# ISS_CCP2 register map
Vendor: Texas Instruments
Peripheral module from a debugger description file (folder omap5430_ES2_PUBLIC).
Registers are 32-bit, access per field, reset values left out (the file's numbers can be read two ways) unless marked. A register's access mark holds for its fields unless they carry their own. Offsets are as the file gives them; lines under a group give offsets from that group; [hi:lo] are bit positions; {n}, {i} and the like mark numbered series; 'fields as' and 'values as' point back to an identical list; <NAME> marks a mode.

## ISS_CCP2
0x00 CCP2_REVISION ro — IP Revision Identifier (X.Y.R) Used by software to track features, bugs, and compatibility
  [31:0] REVISION — IP revision
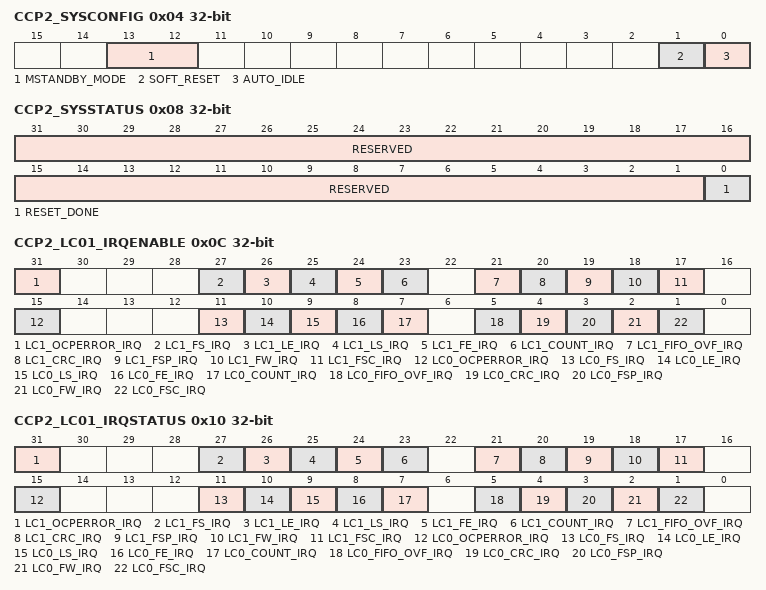
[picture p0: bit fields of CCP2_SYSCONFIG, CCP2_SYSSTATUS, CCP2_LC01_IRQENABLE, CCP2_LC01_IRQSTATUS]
0x04 CCP2_SYSCONFIG — SYSTEM CONFIGURATION REGISTER This register is the OCP-socket system configuration register.
  [13:12] MSTANDBY_MODE rw — Sets the behavior of the master port power management signals.
    0=ForceStby (Force-standby. MStandby is only asserted when the module is disabled.); 1=NoStdby (No-standby. MStandby is never asserted.); 2=SmartStdby (Smart-standby: MStandby is asserted based on the activity of the module. The module will try to go to standby during the vertical blanking period.)
  [1] SOFT_RESET rw — Software reset. Set the bit to 1 to trigger a module reset. The bit is automatically reset by the hardware. During reads return 0.
    0=Normal mode; 1=Reset (The module is reset)
  [0] AUTO_IDLE rw — Internal OCP clock gating strategy.
    0=Free (OCP clock is free-running.); 1=Gated (Automatic OCP clock gating strategy is applied based on the OCP interface activity.)
0x08 CCP2_SYSSTATUS ro — SYSTEM STATUS REGISTER This register provides status information about the module, excluding the interrupt status register.
  [31:1] RESERVED — Write 0's for future compatibility. Reads returns 0.
  [0] RESET_DONE — Internal reset monitoring
    1=ResetCompleted; 0=ResetOngoing (Internal module reset is on going.)
0x0C CCP2_LC01_IRQENABLE — INTERRUPT ENABLE REGISTER - LOG CHAN 0 & 1 This register regroups all the events related to logical channel 0 and logical channel 1. The events related to logical channel 0 trigger SINTERRUPTN[0]. The events related to logical channel 1 trigger SINTERRUPTN[1]. The channel must be enabled for events to be generated on that channel.
  [all] fields
    0=Disable (Event is masked); 1=Enable (Event generates an interrupt when it occurs)
  [31] LC1_OCPERROR_IRQ rw — An OCP error occurred on the master write port.
  [27] LC1_FS_IRQ rw — Logical channel 1 - Frame start sync code detection.
  [26] LC1_LE_IRQ rw — Logical channel 1 - Line end sync code detection.
  [25] LC1_LS_IRQ rw — Logical channel 1 - Line start sync code detection.
  [24] LC1_FE_IRQ rw — Logical channel 1 - Frame end sync code detection.
  [23] LC1_COUNT_IRQ rw — Logical channel 1 - Frame counter reached.
  [21] LC1_FIFO_OVF_IRQ rw — Logical channel 1 - FIFO overflow error.
  [20] LC1_CRC_IRQ rw — Logical channel 1 - CRC error.
  [19] LC1_FSP_IRQ rw — Logical channel 1 - FSP error.
  [18] LC1_FW_IRQ rw — Logical channel 1 - Frame width error.
  [17] LC1_FSC_IRQ rw — Logical channel 1 - False sync code error.
  [15] LC0_OCPERROR_IRQ rw — An OCP error occurred on the master write port.
  [11] LC0_FS_IRQ rw — Logical channel 0 - Frame start sync code detection.
  [10] LC0_LE_IRQ rw — Logical channel 0 - Line end sync code detection.
  [9] LC0_LS_IRQ rw — Logical channel 0 - Line start sync code detection.
  [8] LC0_FE_IRQ rw — Logical channel 0 - Frame end sync code detection.
  [7] LC0_COUNT_IRQ rw — Logical channel 0 - Frame counter reached.
  [5] LC0_FIFO_OVF_IRQ rw — Logical channel 0 - FIFO overflow error.
  [4] LC0_CRC_IRQ rw — Logical channel 0 - CRC error.
  [3] LC0_FSP_IRQ rw — Logical channel 0 - FSP error.
  [2] LC0_FW_IRQ rw — Logical channel 0 - Frame width error.
  [1] LC0_FSC_IRQ rw — Logical channel 0 - False sync code error.
0x10 CCP2_LC01_IRQSTATUS access not given — INTERRUPT STATUS REGISTER - LOG CHAN 0 & 1 This register regroups all the events related to logical channel 0 and logical channel 1. The events related to logical channel 0 trigger SINTERRUPTN[0]. The events related to logical channel 1 trigger SINTERRUPTN[1]. The channel must be enabled for events to be generated on that channel.
  [all] fields
    0=False (READS: Event is false. WRITES: Status bit unchanged.); 1=True (READS: Event is true (pending). WRITES: Status bit is reset.)
  [31] LC1_OCPERROR_IRQ — An OCP error occurred on the master write port. (access RW W1toClr)
  [27] LC1_FS_IRQ — Logical channel 1 - Frame start sync code detection status. (access RW W1toClr)
  [26] LC1_LE_IRQ — Logical channel 1 - Line end sync code detection status. (access RW W1toClr)
  [25] LC1_LS_IRQ — Logical channel 1 - Line start sync code detection status. (access RW W1toClr)
  [24] LC1_FE_IRQ — Logical channel 1 - Frame end sync code detection status. (access RW W1toClr)
  [23] LC1_COUNT_IRQ — Logical channel 1 - Frame counter reached status. (access RW W1toClr)
  [21] LC1_FIFO_OVF_IRQ — Logical channel 1 - FIFO overflow error status. (access RW W1toClr)
  [20] LC1_CRC_IRQ — Logical channel 1 - CRC error status. (access RW W1toClr)
  [19] LC1_FSP_IRQ — Logical channel 1 - FSP error status. (access RW W1toClr)
  [18] LC1_FW_IRQ — Logical channel 1 - Frame width error status. (access RW W1toClr)
  [17] LC1_FSC_IRQ — Logical channel 1 - False sync code error status. (access RW W1toClr)
  [15] LC0_OCPERROR_IRQ — An OCP error occurred on the master write port. (access RW W1toClr)
  [11] LC0_FS_IRQ — Logical channel 0 - Frame start sync code detection status. (access RW W1toClr)
  [10] LC0_LE_IRQ — Logical channel 0 - Line end sync code detection status. (access RW W1toClr)
  [9] LC0_LS_IRQ — Logical channel 0 - Line start sync code detection status. (access RW W1toClr)
  [8] LC0_FE_IRQ — Logical channel 0 - Frame end sync code detection status. (access RW W1toClr)
  [7] LC0_COUNT_IRQ — Logical channel 0 - Frame counter reached status (access RW W1toClr)
  [5] LC0_FIFO_OVF_IRQ — Logical channel 0 - FIFO overflow error status. (access RW W1toClr)
  [4] LC0_CRC_IRQ — Logical channel 0 - CRC error status. (access RW W1toClr)
  [3] LC0_FSP_IRQ — Logical channel 0 - FSP error status. (access RW W1toClr)
  [2] LC0_FW_IRQ — Logical channel 0 - Frame width error status. (access RW W1toClr)
  [1] LC0_FSC_IRQ — Logical channel 0 - False sync code error status. (access RW W1toClr)
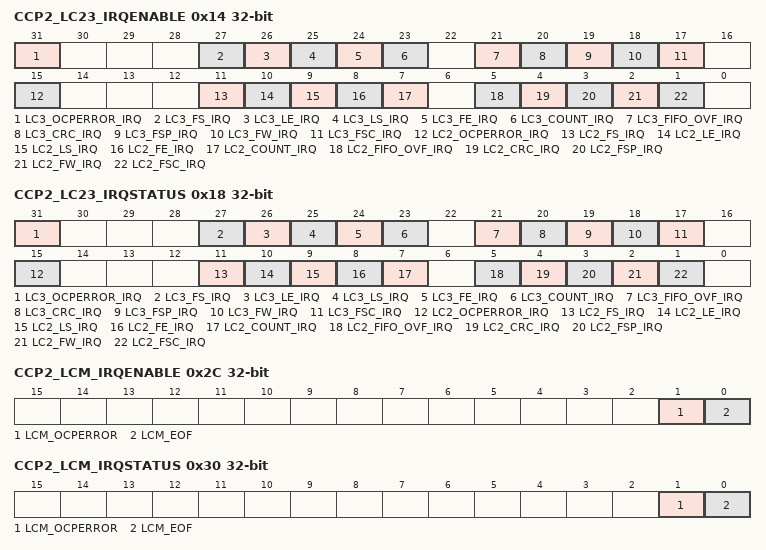
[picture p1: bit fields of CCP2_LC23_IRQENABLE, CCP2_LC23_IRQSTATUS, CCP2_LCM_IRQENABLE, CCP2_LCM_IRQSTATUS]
0x14 CCP2_LC23_IRQENABLE — INTERRUPT ENABLE REGISTER - LOG CHAN 2 & 3 This register regroups all the events related to logical channel 2 and logical channel 3. The events related to logical channel 2 trigger SINTERRUPTN[2]. The events related to logical channel 3 trigger SINTERRUPTN[3]. The channel must be enabled for events to be generated on that channel.
  [all] fields
    values as the fields of CCP2_LC01_IRQENABLE
  [31] LC3_OCPERROR_IRQ rw — An OCP error occurred on the master write port.
  [27] LC3_FS_IRQ rw — Logical channel 3 - Frame start sync code detection.
  [26] LC3_LE_IRQ rw — Logical channel 3 - Line end sync code detection.
  [25] LC3_LS_IRQ rw — Logical channel 3 - Line start sync code detection.
  [24] LC3_FE_IRQ rw — Logical channel 3 - Frame end sync code detection.
  [23] LC3_COUNT_IRQ rw — Logical channel 3 - Frame counter reached.
  [21] LC3_FIFO_OVF_IRQ rw — Logical channel 3 - FIFO overflow error.
  [20] LC3_CRC_IRQ rw — Logical channel 3 - CRC error.
  [19] LC3_FSP_IRQ rw — Logical channel 3 - FSP error.
  [18] LC3_FW_IRQ rw — Logical channel 3 - Frame width error.
  [17] LC3_FSC_IRQ rw — Logical channel 3 - False sync code error.
  [15] LC2_OCPERROR_IRQ rw — An OCP error occurred on the master write port.
  [11] LC2_FS_IRQ rw — Logical channel 2 - Frame start sync code detection.
  [10] LC2_LE_IRQ rw — Logical channel 2 - Line end sync code detection.
  [9] LC2_LS_IRQ rw — Logical channel 2 - Line start sync code detection.
  [8] LC2_FE_IRQ rw — Logical channel 2 - Frame end sync code detection.
  [7] LC2_COUNT_IRQ rw — Logical channel 2 - Frame counter reached.
  [5] LC2_FIFO_OVF_IRQ rw — Logical channel 2 - FIFO overflow error.
  [4] LC2_CRC_IRQ rw — Logical channel 2 - CRC error.
  [3] LC2_FSP_IRQ rw — Logical channel 2 - FSP error.
  [2] LC2_FW_IRQ rw — Logical channel 2 - Frame width error.
  [1] LC2_FSC_IRQ rw — Logical channel 2 - False sync code error.
0x18 CCP2_LC23_IRQSTATUS access not given — INTERRUPT STATUS REGISTER - LOG CHAN 2 & 3 This register regroups all the events related to logical channel 2 and logical channel 3. The events related to logical channel 2 trigger SINTERRUPTN[2]. The events related to logical channel 3 trigger SINTERRUPTN[3]. The channel must be enabled for events to be generated on that channel.
  [all] fields
    values as the fields of CCP2_LC01_IRQSTATUS
  [31] LC3_OCPERROR_IRQ — An OCP error occurred on the master write port. (access RW W1toClr)
  [27] LC3_FS_IRQ — Logical channel 3 - Frame start sync code detection status. (access RW W1toClr)
  [26] LC3_LE_IRQ — Logical channel 3 - Line end sync code detection status. (access RW W1toClr)
  [25] LC3_LS_IRQ — Logical channel 3 - Line start sync code detection status. (access RW W1toClr)
  [24] LC3_FE_IRQ — Logical channel 3 - Frame end sync code detection status. (access RW W1toClr)
  [23] LC3_COUNT_IRQ — Logical channel 3 - Frame counter reached status. (access RW W1toClr)
  [21] LC3_FIFO_OVF_IRQ — Logical channel 3 - FIFO overflow error status. (access RW W1toClr)
  [20] LC3_CRC_IRQ — Logical channel 3 - CRC error status. (access RW W1toClr)
  [19] LC3_FSP_IRQ — Logical channel 3 - FSP error status. (access RW W1toClr)
  [18] LC3_FW_IRQ — Logical channel 3 - Frame width error status. (access RW W1toClr)
  [17] LC3_FSC_IRQ — Logical channel 3 - False sync code error status. (access RW W1toClr)
  [15] LC2_OCPERROR_IRQ — An OCP error occurred on the master write port. (access RW W1toClr)
  [11] LC2_FS_IRQ — Logical channel 2 - Frame start sync code detection status. (access RW W1toClr)
  [10] LC2_LE_IRQ — Logical channel 2 - Line end sync code detection status. (access RW W1toClr)
  [9] LC2_LS_IRQ — Logical channel 2 - Line start sync code detection status. (access RW W1toClr)
  [8] LC2_FE_IRQ — Logical channel 2 - Frame end sync code detection status. (access RW W1toClr)
  [7] LC2_COUNT_IRQ — Logical channel 2 - Frame counter reached status (access RW W1toClr)
  [5] LC2_FIFO_OVF_IRQ — Logical channel 2 - FIFO overflow error status. (access RW W1toClr)
  [4] LC2_CRC_IRQ — Logical channel 2 - CRC error status. (access RW W1toClr)
  [3] LC2_FSP_IRQ — Logical channel 2 - FSP error status. (access RW W1toClr)
  [2] LC2_FW_IRQ — Logical channel 2 - Frame width error status. (access RW W1toClr)
  [1] LC2_FSC_IRQ — Logical channel 2 - False sync code error status. (access RW W1toClr)
0x2C CCP2_LCM_IRQENABLE — INTERRUPT ENABLE REGISTER - Memory channel This register regroups all the events related to the memory channel 2. The events related to memory channel trigger SINTERRUPTN[8]. The channel must be enabled for events to be generated on that channel.
  [1] LCM_OCPERROR rw — An interconnect error has been returned for a read (interconnect read master) or write (interconnect write master) transaction related to LCM operation
    values as the fields of CCP2_LC01_IRQENABLE
  [0] LCM_EOF rw — Memory read channel - End of frame
    values as the fields of CCP2_LC01_IRQENABLE
0x30 CCP2_LCM_IRQSTATUS access not given — INTERRUPT STATUS REGISTER - Memory channel This register regroups all the events related to memory channel. The events related to memory channel trigger SINTERRUPTN[8]. The channel must be enabled for events to be generated on that channel.
  [1] LCM_OCPERROR — An interconnect error has been returned for a read (interconnect read master) or write (interconnect write master) transaction related to LCM operation (access RW W1toClr)
    values as the fields of CCP2_LC01_IRQSTATUS
  [0] LCM_EOF — Memory read channel - End of frame (access RW W1toClr)
    values as the fields of CCP2_LC01_IRQSTATUS
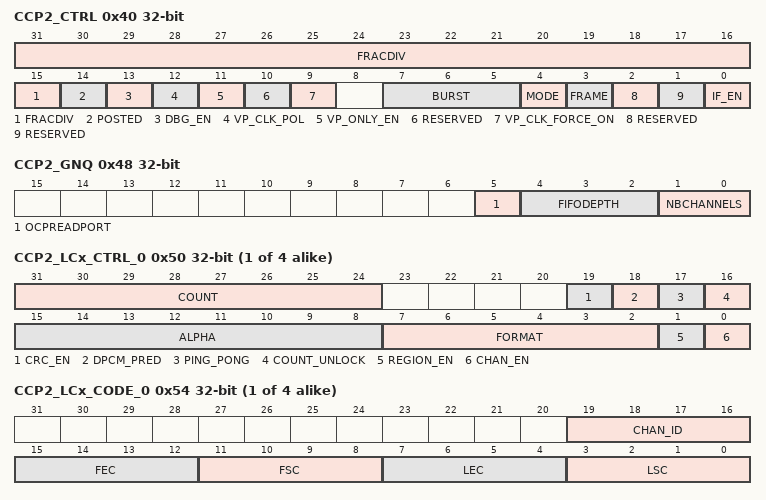
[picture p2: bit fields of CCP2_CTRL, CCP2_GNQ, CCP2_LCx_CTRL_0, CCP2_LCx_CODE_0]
0x40 CCP2_CTRL — GLOBAL CONTROL REGISTER This register controls the CCP2 receiver. This register must not be modified dynamically (except IF_EN bit field).
  [31:15] FRACDIV rw — Fractional clock divider control for the video port. The mean video port clock is VPBASECLOCK * FRACDIV/65536. Valid range: 1-65536
  [14] POSTED rw — Selects between posted and non posted writes.
    0=Posted (Non posted); 1=Posted
  [13] DBG_EN rw — Enables the debug mode.
    0=Disable; 1=Enable
  [12] VP_CLK_POL rw — VP clock polarity
    0=Falling (The CCP2 receiver writes the data on the VP on the L3 falling edge before the next falling PCLK edge.); 1=Rising (The CCP2 receiver writes the data on the VP on the L3 rising edge before the next rising PCLK edge.)
  [11] VP_ONLY_EN rw — VP only enable.
    0=Disable (The VP is enabled and the OCP master port are enabled.); 1=Enable (The VP is enabled and the OCP master port is disabled. The embedded data and pixel data are output on the VP.)
  [10] RESERVED rw — Read returns reset value
  [9] VP_CLK_FORCE_ON rw — Controls VP_PCLK gating during frame blanking periods.
    0=GATED (The VP_PCLK is gated during vertical blanking periods.); 1=FREE_RUNNING (The VP_PCLK is free-running during vertical blanking periods.)
  [7:5] BURST rw — Forces the write burst size used by the module. The write burst size must never exceed the output FIFO size. The output FIFO size can be read with the CCP2_GNQ.FIFODEPTH bit field.
    0=B1x64 (1x 64-bit burst = single request.); 1=B2x64 (2x 64-bit bursts.); 3=B8x64 (8x 64-bit bursts.); 4=B16x64 (16x 64-bit bursts.); 2=B4x64 (4x 64-bit bursts.)
  [4] MODE rw — Selects the receiver operating mode. This bit is only writable when the CCP2MODE input is 1.
    0=CCP1 (MIPI CSI1 compatible mode. When this bit is set all CCP2 settings are ignored. If the settings are not set correctly to MIPI CSI1 values, the behavior of the receiver is unpredictable.); 1=CCP2 (CCP2 compatible mode)
  [3] FRAME rw — Set the modality in which IF_EN works.
    0=Immediate (When software writes IF_EN = 0 the interface is disabled immediately.); 1=Frame (When software writes IF_EN = 0 the interface is disabled after the next FEC sync code.)
  [2] RESERVED rw — Read returns reset value
  [1] RESERVED rw — Read returns reset value
  [0] IF_EN rw — Enables the physical interface to the module.
    0=Disable (The interface is disabled. If FRAME = 0, it is disabled immediately. If FRAME = 1, it is disabled on the next FEC sync code. If FRAME=1, it is advised to disable the logical channels first (.CHAN_EN=0) before writing IF_EN=0.); 1=Enable (The interface is enabled immediately, the data acquisition starts on the next FSC sync code. Writing 1 to this register when the current value is 0 has the effect to clear the output FIFO. The pixel data of the following frame will be written in the PING buffer, that is, the .PING_PONG bits are reset to 1 as well.)
0x44 CCP2_DBG wo — DEBUG REGISTER This register provides a way to debug the CCP2 receiver with no image sensor connected to the module. The debug mode is enabled by .DBG_EN. Each write to this register provides a full 32bit word to the CCP2 receiver, even when only 8 or 16 bits are written. The newly written value is merged with the previous value (check the example in the programming model section).
  [31:0] DBG — 32-bit input value. Write only register. Reads return 0.
0x48 CCP2_GNQ ro — GENERIC PARAMETER REGISTER This register provide a way to read the generic parameters used in the design.
  [5] OCPREADPORT — The OCP master read port, the DPCM encoder and ALAW decompression are only present when this bit is set.
  [4:2] FIFODEPTH — Output FIFO size in multiple of 64 bits.
    3=f16 (16 x 64 bits); 4=f32 (32 x 64 bits); 2=f8 (8 x 64 bits); 0=f3 (2 x 64 bits); 1=f4 (4 x 64 bits); 5=f64 (64 x 64 bits)
  [1:0] NBCHANNELS — Number of logical channels supported by the module.
    3=lc8 (8 logical channels); 2=lc4 (4 logical channels); 1=lc2 (2 logical channels); 0=lc1 (1 logical channel)
0x4C CCP2_CTRL1 access not given — GLOBAL CONTROL REGISTER (2) This register controls the CCP2 receiver.
  [1:0] BLANKING rw — Controls the number of clock pulses provided during vertical and horizontal clock periods. When the blanking period provided by the camera is lower than the value set here, the blanking period is shortened by the CCP2 to prevent internal FIFO overflow. Software must increase the sensor blanking period in that case.
    0=4_video_port_clock_cycles; 1=16_video_port_clock_cycles; 2=64_video_port_clock_cycles; 3=Free_running
{0x50+0x30*i} CCP2_LCx_CTRL_{i} (i=0..3) — CONTROL REGISTER - LOG CHAN 0 This register controls the logical channel 0. This register is shadowed: modifications are taken into account after the next FSC sync code.
  [31:24] COUNT rw — Sets the number of frame to acquire. Once the frame acquisition starts, the COUNT value is decremented after every frame. When COUNT reaches 0, the COUNT_IRQ interrupt is triggered and CHAN_EN is set to 0. Writes to this bit field are controlled by the COUNT_UNLOCK bit. COUNT can be overwritten dynamically with a new count value. 0: Infinite number of frames (no count). 1: 1 frame to acquire ... 255: 255 frames to acquire.
  [19] CRC_EN rw — Enables the cyclic redundancy check.
    0=Disabled; 1=Enabled
  [18] DPCM_PRED rw — Selects the DPCM predictor to be used for the RAW6+DPCM10, RAW7+DPCM10 and RAW8+DPCM12 data formats. The RAW8+DPCM10 data format always use the simple predictor.
    0=The_advanced_predictor_is_used; 1=The_simple_predictor_is_used
  [17] PING_PONG ro — Indicates whether the PING or PONG destination address (CCP2_LC0_DAT_PING_ADDR or CCP2_LC0_DAT_PONG_ADDR) was used to write the last frame. This bit field toggles after every FEC sync code.
    1=PONG_buffer; 0=PING_buffer
  [16] COUNT_UNLOCK wo — Unlock writes to the COUNT bit field.
    0=COUNT_0 (COUNT bit field is locked. Writes have no effect); 1=COUNT_1 (COUNT bit field is unlocked. Writes are possible.)
  [15:8] ALPHA rw — Alpha value for RGB888 and RBG444.
  [7:2] FORMAT rw — Data format selection.
    13=RAW7_+_DPCM10_+_EXP16; 21=RAW10_+_EXP16; 30=RAW10_RAW8_RAW10_RAW8_30 (RAW10 -> RAW8 RAW10 data from sensor is right shifted to produce RAW8 before it is send to memory); 8=RAW6_+_EXP8; 5=RGB565; 27=RAW10_RAW8_DPCM_RAW10_DPCM_RAW8_27 (RAW10 -> RAW8 DPCM RAW10 data from sensor is DPCM compressed into RAW8 before it is send to memory.); 2=YUV4:2:0; 4=RGB444_+_EXP16; 6=RGB888; 1=YUV4:2:2_LITTLE_ENDIAN; 29=JPEG8; 0=YUV4:2:2_BIG_ENDIAN; 11=RAW10_RAW6_DPCM_RAW10_DPCM_RAW6_DPCM_PRED_11 (RAW10 -> RAW6 DPCM RAW10 data from sensor is DPCM compressed into RAW6 before it is send to memory. Used predictor is selected by the DPCM_PRED bit.); 32=RAW10_->_RAW8_ALAW; 3=YUV4:2:2_+_VP_or_RAW8_+_VP; 23=RAW10_RAW7_DPCM_EXP8_RAW10_DPCM_RAW7_DPCM_PRED_23 (RAW10 -> RAW7 DPCM + EXP8 RAW10 data from sensor is DPCM compressed into RAW7 and expanded to 8 bits before it is send to memory. Used predictor is selected by the DPCM_PRED bit.); 17=RAW8_+_DPCM10_+_EXP16; 10=RAW6_+_DPCM10_+_VP; 9=RAW6_+_DPCM10_+_EXP16; 16=RAW8_RAW6_RAW7_16 (RAW8 This mode can be used to output RAW6 and RAW7 as well.); 33=RAW8_DPCM10_->_ALAW; 18=RAW8_+_DPCM10_+_VP; 19=RAW10_RAW7_DPCM_RAW10_DPCM_RAW7_DPCM_PRED_19 (RAW10 -> RAW7 DPCM RAW10 data from sensor is DPCM compressed into RAW7 before it is send to memory. Used predictor is selected by the DPCM_PRED bit.); 24=RAW12; 20=RAW10; 14=RAW7_+_DPCM10_+_VP; 22=RAW10_+_VP; 28=JPEG8_+_FSP; 7=RGB888_+_EXP32; 25=RAW12_+_EXP16; 31=RAW8_DPCM12_RAW12_VP_DPCM_PRED_31 (RAW8 DPCM12 -> RAW12 + VP Used predictor is selected by the DPCM_PRED bit.); 26=RAW12_+_VP; 15=RAW10_RAW6_DPCM_EXP8_RAW10_DPCM_RAW6_DPCM_PRED_15 (RAW10 -> RAW6 DPCM + EXP8 RAW10 data from sensor is DPCM compressed into RAW6 and expanded to 8 bits before it is send to memory. Used predictor is selected by the DPCM_PRED bit.); 12=RAW7_+_EXP8
  [1] REGION_EN rw — Enables the setting of regions of interest in the frame: SOF region, EOF region and DAT region.
    0=Disabled; 1=Enabled
  [0] CHAN_EN rw — Enables the logical channel0x0 for LC3 .
{0x54+0x30*i} CCP2_LCx_CODE_{i} (i=0..3) — CODE REGISTER - LOG CHAN 0 This register sets the codes that are used in the 32-bit synchronization codes to recognize the logical channel, frame start, frame end, line start and line end codes. This register applies for logical channel 0 only. The default values are usually not supposed to be modified. Updating this register with new codes under a flowing serial transmission on that channel will cause unexpected result.
  [19:16] CHAN_ID rw — Log chan 0 identifier. The channel identifier is located between bits 4 to 7 in the 32-bit synchronization codes.
  [15:12] FEC rw — Log chan 0 frame end sync code identifier. The sync code identifier is located between bits 0 to 3 in the 32-bit synchronization codes.
  [11:8] FSC rw — Log chan 0 frame start sync code identifier. The sync code identifier is located between bits 0 to 3 in the 32-bit synchronization codes.
  [7:4] LEC rw — Log chan 0 line end sync code identifier. The sync code identifier is located between bits 0 to 3 in the 32-bit synchronization codes.
  [3:0] LSC rw — Log chan 0 line start sync code identifier. The sync code identifier is located between bits 0 to 3 in the 32-bit synchronization codes.
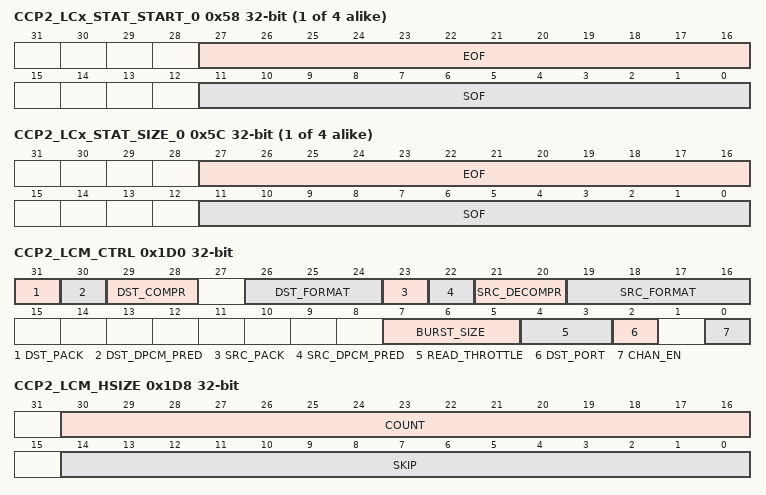
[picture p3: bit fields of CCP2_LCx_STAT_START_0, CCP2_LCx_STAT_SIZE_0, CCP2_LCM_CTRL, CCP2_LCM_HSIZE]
{0x58+0x30*i} CCP2_LCx_STAT_START_{i} (i=0..3) — STATUS LINE START REGISTER - LOG CHAN 0 This register is shadowed: modifications are taken into account after the next FSC sync code.
  [27:16] EOF rw — Sets the vertical position of the EOF status lines in regards of the FSC sync code. From 0 to 4095.
  [11:0] SOF rw — Sets the vertical position of the EOF status lines in regards of the FSC sync code. Should always be 0.
{0x5C+0x30*i} CCP2_LCx_STAT_SIZE_{i} (i=0..3) — STATUS LINE SIZE REGISTER - LOG CHAN 0 This register is shadowed: modifications are taken into account after the next FSC sync code.
  [27:16] EOF rw — Sets the number of EOF status lines From 0 to 4095
  [11:0] SOF rw — Sets the number of SOF status line(s) From 0 to 4095
{0x60+0x30*i} CCP2_LCx_SOF_ADDR_{i} (i=0..3) — SOF STATUS LINE MEM ADDRESS REGISTER - LOG CHAN 0 This register sets the 32-bit memory address where the SOF data are stored. The 5 LSBs are ignored: the address must be aligned on a 32-byte boundary. This register is shadowed: modifications are taken into account after the next FSC sync code.
  [31:5] ADDR rw — 27 most significant bits of the 32-bit address.
{0x64+0x30*i} CCP2_LCx_EOF_ADDR_{i} (i=0..3) — EOF STATUS LINE MEM ADDRESS REGISTER - LOG CHAN 0 This register sets the 32-bit memory address where the EOF data are stored. The 5 LSBs are ignored: the address must be aligned on a 32-byte boundary. This register is shadowed: modifications are taken into account after the next FSC sync code.
  [31:5] ADDR rw — 27 most significant bits of the 32-bit address.
{0x68+0x30*i} CCP2_LCx_DAT_START_{i} (i=0..3) — DATA START REGISTER - LOG CHAN 0 This register is shadowed: modifications are taken into account after the next FSC sync code.
  [27:16] VERT rw — Sets the vertical position of the data in regards of the FSC sync code. From 0 to 4095 lines.
{0x6C+0x30*i} CCP2_LCx_DAT_SIZE_{i} (i=0..3) — DATA SIZE REGISTER - LOG CHAN 0 This register is shadowed: modifications are taken into account after the next FSC sync code.
  [27:16] VERT rw — Sets the vertical size of the data window. From 0 to 4095 lines. If VERT = '0', no data is output.
{0x70+0x30*i} CCP2_LCx_DAT_PING_ADDR_{i} (i=0..3) — DATA MEM PING ADDRESS REGISTER - LOG CHAN 0 This register sets the 32-bit memory address where the pixel data are stored. The destination is double buffered: this register sets the PING address. Double buffering is enabled when the addresses CCP2_LC0_DAT_PING_ADDR and CCP2_LC0_DAT_PONG_ADDR are different. The 5 LSBs are ignored: the address must be aligned on a 32-byte boundary. This register is shadowed: modifications are taken into account after the next FSC sync code.
  [31:5] ADDR rw — 27 most significant bits of the 32-bit address.
{0x74+0x30*i} CCP2_LCx_DAT_PONG_ADDR_{i} (i=0..3) — DATA MEM PONG ADDRESS REGISTER - LOG CHAN 0 This register sets the 32-bit memory address where the pixel data are stored. The destination is double buffered: this register sets the PONG address. Double buffering is enabled when the addresses CCP2_LC0_DAT_PING_ADDR and CCP2_LC0_DAT_PONG_ADDR are different. The 5 LSBs are ignored: the address must be aligned on a 32-byte boundary. This register is shadowed: modifications are taken into account after the next FSC sync code.
  [31:5] ADDR rw — 27 most significant bits of the 32-bit address.
{0x78+0x30*i} CCP2_LCx_DAT_OFST_{i} (i=0..3) — DATA MEM ADDRESS OFFSET REGISTER - LOG CHAN 0 This register sets the offset, which is applied on the destination address after each line is written to memory. This register applies for both CCP2_LC0_DAT_PING_ADDR and CCP2_LC0_DAT_PONG_ADDR. For example, it enables to perform 2D data transfers of the pixel data into a frame buffer. In such case, the pixel data and frame buffer data must have the same data format. The 5 LSBs are ignored: the offset must be a multiple of 32 bytes. Only full 64-bits words are written to memory at the end of lines. This register is shadowed: modifications are taken into account after the next FSC sync code.
  [31:5] OFST rw — Line offset programmed in bytes. If OFST = 0, the data is written contiguously in memory. Otherwise, OFST sets the destination offset between the first pixel of the previous line and the first pixel of the current line. NOTE: An OCP access (read/write) is required to properly update the CCP2_LCx_DAT_OFST register
0x1D0 CCP2_LCM_CTRL — Control register for the memory channel. It defines the data format of the source frame stored in memory and how this frame is processed.
  [31] DST_PACK rw — Data is packed before it is send to memory. Applies to RAW6, RAW7, RAW10, and RAW12 only.
    0=DISABLE (Disabled); 1=ENABLE (Enabled)
  [30] DST_DPCM_PRED rw — Selects the DPCM predictor to be used for the RAW6+DPCM10 and RAW7+DPCM10 data formats. The RAW8+DPCM10 data format always use the simple predictor.
    0=Advanced (The advanced predictor is used); 1=Simple (The simple predictor is used.)
  [29:28] DST_COMPR rw — Enables data compression of data sent to memory
    0=DISABLE (No compression); 1=ALAW (A-Law compression RAW10 -> RAW8 A-Law when DST_FORMAT=RAW8 other destination formats are invalid.); 2=DPCM (DPCM compression RAW10 -> RAW6 DPCM when DST_FORMAT=RAW6 RAW10 -> RAW7 DPCM when DST_FORMAT=RAW7 RAW10 -> RAW8 DPCM when DST_FORMAT=RAW8 other destination formats are invalid.)
  [26:24] DST_FORMAT rw — Output format selection. Not every combination between input and output formats are possible.
    6=RAW16; 1=RAW7; 0=RAW6; 2=RAW8; 4=RAW12; 5=RAW14; 3=RAW10
  [23] SRC_PACK rw — Data stored in memory is packed and must be unpacked.
    0=DISABLE (Disabled); 1=ENABLE (Enabled)
  [22] SRC_DPCM_PRED rw — Selects the DPCM predictor to be used for the RAW6+DPCM10, RAW7+DPCM10 and RAW8+DPCM12 data formats. The RAW8+DPCM10 and RAW6 + DPCM12 data format always use the simple predictor.
    values as DST_DPCM_PRED
  [21:20] SRC_DECOMPR rw — Enable decompression of incoming data
    0=DISABLE (No decompression); 1=ALAW (A-Law decompression RAW8 A-Law -> RAW10 when SRC_FORMAT=RAW8 other source formats are invalid.); 3=DPCM12 (DPCM decompression RAW6 DPCM -> RAW12 when SRC_FORMAT=RAW6 RAW8 DPCM -> RAW12 when SRC_FORMAT=RAW8 other source formats are invalid.); 2=DPCM (DPCM decompression RAW6 DPCM -> RAW10 when SRC_FORMAT=RAW6 RAW7 DPCM -> RAW10 when SRC_FORMAT=RAW7 RAW8 DPCM -> RAW10 when SRC_FORMAT=RAW8 other source formats are invalid.)
  [19:16] SRC_FORMAT rw — Data format of the data stored in memory. As there is no header embedded in the data sent to memory the user is responsible of choosing the adequate format.
    6=RAW16; 1=RAW7; 10=RSZ (Reserved); 7=RSZ (Reserved); 0=RAW6; 2=RAW8; 8=RGB666_to_RGGB (Reserved); 9=RGB666_to_GRBG (Reserved); 11=RGB666_to_GRBG (Reserved); 4=RAW12; 5=RAW14; 15=RAW14 (Reserved); 3=RAW10; 14=RAW10 (Reserved)
  [7:5] BURST_SIZE rw — Defines the burst size of the master read port
    values as CCP2_CTRL.BURST
  [4:3] READ_THROTTLE rw — Limit maximum data read speed for memory to memory operation
    0=FULL (Full speed. Throughput is limited by internal processing capabilities.); 1=TWO (1/2 speed); 3=EIGHT (1/8 speed); 2=FOUR (1/4 speed)
  [2] DST_PORT rw — Select the destination port
    0=VPORT (Data is send to video port, it is always send without compression or packing. The DST_COMPR, DST_DPCM_PRED, DST_PACK, CCP2_LCM_DST_WRITE, and registers have no effect.); 1=MEMWRITE (Data is send to memory.)
  [0] CHAN_EN rw — Enables the read from memory channel. Before enabling the memory read channel software must: - disable the physical interface using the IF_EN bit - wait until disabling of the physical interface is effective (depends on the FRAME bit) Read from memory starts as soon as this bit is set, therefore all CCP2_LCM_x registers must be configured correctly before. This bit is cleared by hardware at the end of the frame.
    0=Disabled; 1=Enabled
0x1D4 CCP2_LCM_VSIZE — Memory channel vertical framing register
  [28:16] COUNT rw — Defines the line count to be read from memory. From 1 to 8191 lines.
0x1D8 CCP2_LCM_HSIZE — Memory read channel horizontal framing register.
  [30:16] COUNT rw — Horizontal count ofsamples to output after the skipped pixels. Valid values: 1 to 32767.
  [14:0] SKIP rw — Horizontal count ofsamples to skip after the start of the line. When DPCM compressed data is read from memory using this feature is the only valid way to set a horizontal starting position. Valid values: 0 to32767. 0 disables pixel skipping
0x1DC CCP2_LCM_PREFETCH — This register defines the amount of data to be fetched from memory. It must be consistent with the register (check programming model).
  [15:3] HWORDS rw — 64 bit words to read from memory for each line of the image. Possible values 1..8191
0x1E0 CCP2_LCM_SRC_ADDR — Memory channel source address register This register sets the 32-bit memory address where the pixel data are stored. The 5 LSBs are ignored: the address must be aligned on a 32-byte boundary.
  [31:5] ADDR rw — 27 most-significant bits of the 32-bit address
0x1E4 CCP2_LCM_SRC_OFST — Memory channel source offset register. This register sets the offset, which is applied on the source address after each line is read from memory. For example, it enables to perform 2D data transfers of the pixel data from a frame buffer. In such case, the pixel data and frame buffer data must have the same data format. The 5 LSBs are ignored: the offset must be a multiple of 32 bytes.
  [31:5] OFST rw — Line offset programmed in bytes. If OFST = 0, the data is read contiguously from memory. Otherwise, OFST sets the source offset between the first pixel of the previous line and the first pixel of the current line.
0x1E8 CCP2_LCM_DST_ADDR — Memory channel destination address. This register sets the 32-bit memory address where the pixel data are stored. The 5 LSBs are ignored: the address must be aligned on a 32-byte boundary.
  [31:5] ADDR rw — 27 most significant bits of the 32-bit address.
0x1EC CCP2_LCM_DST_OFST — Memory channel destination offset register. This register sets the offset, which is applied on the destination address after each line is written to memory. For example, it enables to perform 2D data transfers of the pixel data into a frame buffer. In such case, the pixel data and frame buffer data must have the same data format. The 5 LSBs are ignored: the offset must be a multiple of 32 bytes.
  [31:5] OFST rw — Line offset programmed in bytes. If OFST = 0, the data is written contiguously to memory if possible. At the end of a line only full 32 bit words will be written, creating eventually gaps at the end of lines. Otherwise, OFST sets the destination offset between the first pixel of the previous line and the first pixel of the current line.
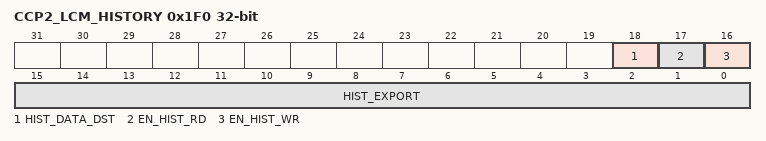
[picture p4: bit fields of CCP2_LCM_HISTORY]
0x1F0 CCP2_LCM_HISTORY — Controls operation of the DPCM history read/write feature
  [18] HIST_DATA_DST rw — Selects destination of pixel data
    0=VP (History data is send to OCP port Pixel data is send to video port); 1=OCP (History data is send to OCP port Pixel data is send to OCP port)
  [17] EN_HIST_RD rw — Enable DPCM history read
    0=newEnum2 (Disable); 1=newEnum1 (Enable)
  [16] EN_HIST_WR rw — Enable DPCM history write
    0=newEnum2 (Disable); 1=newEnum1 (Enable)
  [15:0] HIST_EXPORT rw — Defines the horizontal position at which DPCM history information is written. The first decoded sample of a line has position 0 The last decoded sample has position SKIP+COUNT–1 Valid range [3..SKIP+COUNT–1]
0x1F4 CCP2_LCM_HIST_ADDR — Source and destination address in SDRAM of HISTORY data when[18] HIST_DATA_DST=1 Unused when [18] HIST_DATA_DST=0
  [31:5] ADDR rw — 27 most significant bits of the 32-bit address.
